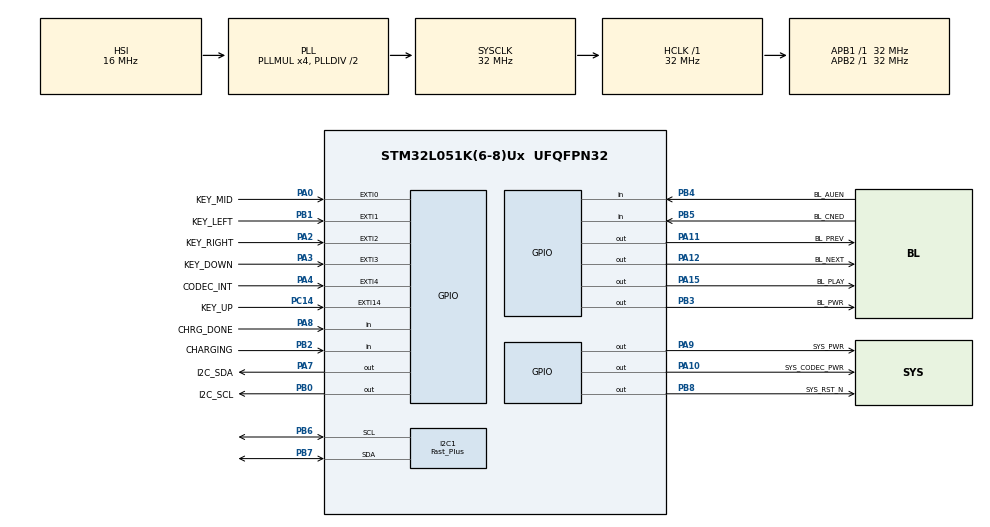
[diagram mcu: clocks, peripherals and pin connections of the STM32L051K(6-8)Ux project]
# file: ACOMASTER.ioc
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Dma.I2C1_TX.0.Direction=DMA_MEMORY_TO_PERIPH
Dma.I2C1_TX.0.Instance=DMA1_Channel2
Dma.I2C1_TX.0.MemDataAlignment=DMA_MDATAALIGN_BYTE
Dma.I2C1_TX.0.MemInc=DMA_MINC_ENABLE
Dma.I2C1_TX.0.Mode=DMA_NORMAL
Dma.I2C1_TX.0.PeriphDataAlignment=DMA_PDATAALIGN_BYTE
Dma.I2C1_TX.0.PeriphInc=DMA_PINC_DISABLE
Dma.I2C1_TX.0.Priority=DMA_PRIORITY_LOW
Dma.Request0=I2C1_TX
I2C1.I2C_Speed_Mode=I2C_Fast_Plus
I2C1.Timing=0x0040040C
Mcu.Family=STM32L0
Mcu.Name=STM32L051K(6-8)Ux
Mcu.Package=UFQFPN32
NVIC.DMA1_Channel2_3_IRQn=true\:1\:0\:true\:false\:true\:false\:true\:true
NVIC.EXTI0_1_IRQn=true\:1\:0\:true\:false\:true\:true\:true\:true
NVIC.EXTI2_3_IRQn=true\:1\:0\:true\:false\:true\:true\:true\:true
NVIC.EXTI4_15_IRQn=true\:1\:0\:true\:false\:true\:true\:true\:true
NVIC.FLASH_IRQn=true\:2\:0\:true\:false\:true\:true\:true\:true
NVIC.I2C1_IRQn=true\:1\:0\:true\:false\:true\:true\:true\:true
NVIC.RTC_IRQn=true\:1\:0\:true\:false\:true\:true\:true\:true
NVIC.TIM21_IRQn=true\:3\:0\:true\:false\:true\:true\:true\:true
NVIC.TIM6_DAC_IRQn=true\:2\:0\:true\:false\:true\:true\:true\:true
PA0.GPIO_Label=KEY_MID
PA0.GPIO_ModeDefaultEXTI=GPIO_MODE_IT_RISING
PA0.GPIO_PuPd=GPIO_PULLDOWN
PA0.Signal=GPXTI0
PA10.GPIO_Label=SYS_CODEC_PWR
PA10.Signal=GPIO_Output
PA11.GPIO_Label=BL_PREV
PA11.Signal=GPIO_Output
PA12.GPIO_Label=BL_NEXT
PA12.Signal=GPIO_Output
PA13.Mode=Serial_Wire
PA13.Signal=SYS_SWDIO
PA14.Mode=Serial_Wire
PA14.Signal=SYS_SWCLK
PA15.GPIO_Label=BL_PLAY
PA15.Signal=GPIO_Output
PA2.GPIO_Label=KEY_RIGHT
PA2.GPIO_ModeDefaultEXTI=GPIO_MODE_IT_FALLING
PA2.GPIO_PuPd=GPIO_PULLUP
PA2.Signal=GPXTI2
PA3.GPIO_Label=KEY_DOWN
PA3.GPIO_ModeDefaultEXTI=GPIO_MODE_IT_FALLING
PA3.GPIO_PuPd=GPIO_PULLUP
PA3.Signal=GPXTI3
PA4.GPIO_Label=CODEC_INT
PA4.GPIO_ModeDefaultEXTI=GPIO_MODE_IT_FALLING
PA4.Signal=GPXTI4
PA7.GPIO_Label=I2C_SDA
PA7.GPIO_ModeDefaultOutputPP=GPIO_MODE_OUTPUT_OD
PA7.GPIO_PuPd=GPIO_NOPULL
PA7.GPIO_Speed=GPIO_SPEED_FREQ_VERY_HIGH
PA7.PinState=GPIO_PIN_SET
PA7.Signal=GPIO_Output
PA8.GPIO_Label=CHRG_DONE
PA8.GPIO_PuPd=GPIO_PULLUP
PA8.Signal=GPIO_Input
PA9.GPIO_Label=SYS_PWR
PA9.Signal=GPIO_Output
PB0.GPIO_Label=I2C_SCL
PB0.GPIO_ModeDefaultOutputPP=GPIO_MODE_OUTPUT_OD
PB0.GPIO_PuPd=GPIO_NOPULL
PB0.GPIO_Speed=GPIO_SPEED_FREQ_VERY_HIGH
PB0.PinState=GPIO_PIN_SET
PB0.Signal=GPIO_Output
PB1.GPIO_Label=KEY_LEFT
PB1.GPIO_ModeDefaultEXTI=GPIO_MODE_IT_FALLING
PB1.GPIO_PuPd=GPIO_PULLUP
PB1.Signal=GPXTI1
PB2.GPIO_Label=CHARGING
PB2.GPIO_PuPd=GPIO_PULLUP
PB2.Signal=GPIO_Input
PB3.GPIO_Label=BL_PWR
PB3.PinState=GPIO_PIN_RESET
PB3.Signal=GPIO_Output
PB4.GPIO_Label=BL_AUEN
PB4.Signal=GPIO_Input
PB5.GPIO_Label=BL_CNED
PB5.Signal=GPIO_Input
PB6.Mode=I2C
PB6.Signal=I2C1_SCL
PB7.Mode=I2C
PB7.Signal=I2C1_SDA
PB8.GPIO_Label=SYS_RST_N
PB8.PinState=GPIO_PIN_SET
PB8.Signal=GPIO_Output
PC14-OSC32_IN.GPIO_Label=KEY_UP
PC14-OSC32_IN.GPIO_ModeDefaultEXTI=GPIO_MODE_IT_FALLING
PC14-OSC32_IN.GPIO_PuPd=GPIO_PULLUP
PC14-OSC32_IN.Signal=GPXTI14
ProjectManager.HeapSize=0x200
ProjectManager.StackSize=0x400
ProjectManager.TargetToolchain=MDK-ARM V5.32
RCC.AHBFreq_Value=32000000
RCC.APB1Freq_Value=32000000
RCC.APB1TimFreq_Value=32000000
RCC.APB2Freq_Value=32000000
RCC.APB2TimFreq_Value=32000000
RCC.HCLKFreq_Value=32000000
RCC.HSI16_VALUE=16000000
RCC.HSI_VALUE=16000000
RCC.LSE_VALUE=32768
RCC.MSI_VALUE=2097000
RCC.PLLMUL=RCC_PLLMUL_4
RCC.SYSCLKFreq_VALUE=32000000
RCC.SYSCLKSource=RCC_SYSCLKSOURCE_PLLCLK
RCC.VCOOutputFreq_Value=64000000
RTC.WakeUpClock=RTC_WAKEUPCLOCK_CK_SPRE_16BITS
RTC.WakeUpCounter=10
TIM21.AutoReloadPreload=TIM_AUTORELOAD_PRELOAD_ENABLE
TIM21.Period=499
TIM21.Prescaler=319
TIM22.Prescaler=31
TIM6.AutoReloadPreload=TIM_AUTORELOAD_PRELOAD_ENABLE
TIM6.Period=9999
TIM6.Prescaler=319
VP_RTC_VS_RTC_Activate.Mode=RTC_Enabled
VP_RTC_VS_RTC_WakeUp_intern.Mode=WakeUp
VP_TIM21_VS_ClockSourceITR.Mode=TriggerSource_ITR0
VP_TIM22_VS_ClockSourceITR.Mode=TriggerSource_ITR0
VP_TIM6_VS_ClockSourceINT.Mode=Enable_Timer
board=custom

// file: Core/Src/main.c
/* USER CODE BEGIN Header */
/**
  ******************************************************************************
  * @file           : main.c
  * @brief          : Main program body
  ******************************************************************************
  * @attention
  *
  * Copyright (c) 2023 STMicroelectronics.
  * All rights reserved.
  *
  * This software is licensed under terms that can be found in the LICENSE file
  * in the root directory of this software component.
  * If no LICENSE file comes with this software, it is provided AS-IS.
  *
  ******************************************************************************
  */
/* USER CODE END Header */
#include "main.h"
#include "dma.h"
#include "i2c.h"
#include "rtc.h"
#include "tim.h"
#include "gpio.h"

/* USER CODE BEGIN Includes */
#include "tasks.h"

#include "eeprom.h"
/* USER CODE END Includes */

/* USER CODE BEGIN PV */
uint8_t wd[5] = {0x45, 0xa7, 0x78, 0xfc, 0x01};
uint8_t rd[5] = {0x00};

/* USER CODE END PV */

void SystemClock_Config(void);

int main(void)
{

  /* MCU Configuration--------------------------------------------------------*/

  /* Reset of all peripherals, Initializes the Flash interface and the Systick. */
  HAL_Init();

  /* Configure the system clock */
  SystemClock_Config();

  /* Initialize all configured peripherals */
  MX_GPIO_Init();
  MX_DMA_Init();
  MX_TIM22_Init();
  MX_TIM21_Init();
  MX_TIM6_Init();
  MX_I2C1_Init();
  MX_RTC_Init();
  /* USER CODE BEGIN 2 */

	//这里先不使能RTC中断，设备息屏前再使能，重新生成代码后要修改rtc.c

  /* USER CODE END 2 */

  /* Infinite loop */
  /* USER CODE BEGIN WHILE */
  while (1)
  {

		main_FSM(&device_current_state, &device_last_state, 1);

		HAL_Delay(1);

    /* USER CODE END WHILE */

  }
}

void SystemClock_Config(void)
{
  RCC_OscInitTypeDef RCC_OscInitStruct = {0};
  RCC_ClkInitTypeDef RCC_ClkInitStruct = {0};
  RCC_PeriphCLKInitTypeDef PeriphClkInit = {0};

  /** Configure the main internal regulator output voltage
  */
  __HAL_PWR_VOLTAGESCALING_CONFIG(PWR_REGULATOR_VOLTAGE_SCALE1);

  /** Initializes the RCC Oscillators according to the specified parameters
  * in the RCC_OscInitTypeDef structure.
  */
  RCC_OscInitStruct.OscillatorType = RCC_OSCILLATORTYPE_HSI|RCC_OSCILLATORTYPE_LSI;
  RCC_OscInitStruct.HSIState = RCC_HSI_ON;
  RCC_OscInitStruct.HSICalibrationValue = RCC_HSICALIBRATION_DEFAULT;
  RCC_OscInitStruct.LSIState = RCC_LSI_ON;
  RCC_OscInitStruct.PLL.PLLState = RCC_PLL_ON;
  RCC_OscInitStruct.PLL.PLLSource = RCC_PLLSOURCE_HSI;
  RCC_OscInitStruct.PLL.PLLMUL = RCC_PLLMUL_4;
  RCC_OscInitStruct.PLL.PLLDIV = RCC_PLLDIV_2;
  if (HAL_RCC_OscConfig(&RCC_OscInitStruct) != HAL_OK)
  {
    Error_Handler();
  }

  /** Initializes the CPU, AHB and APB buses clocks
  */
  RCC_ClkInitStruct.ClockType = RCC_CLOCKTYPE_HCLK|RCC_CLOCKTYPE_SYSCLK
                              |RCC_CLOCKTYPE_PCLK1|RCC_CLOCKTYPE_PCLK2;
  RCC_ClkInitStruct.SYSCLKSource = RCC_SYSCLKSOURCE_PLLCLK;
  RCC_ClkInitStruct.AHBCLKDivider = RCC_SYSCLK_DIV1;
  RCC_ClkInitStruct.APB1CLKDivider = RCC_HCLK_DIV1;
  RCC_ClkInitStruct.APB2CLKDivider = RCC_HCLK_DIV1;

  if (HAL_RCC_ClockConfig(&RCC_ClkInitStruct, FLASH_LATENCY_1) != HAL_OK)
  {
    Error_Handler();
  }
  PeriphClkInit.PeriphClockSelection = RCC_PERIPHCLK_I2C1|RCC_PERIPHCLK_RTC;
  PeriphClkInit.I2c1ClockSelection = RCC_I2C1CLKSOURCE_PCLK1;
  PeriphClkInit.RTCClockSelection = RCC_RTCCLKSOURCE_LSI;
  if (HAL_RCCEx_PeriphCLKConfig(&PeriphClkInit) != HAL_OK)
  {
    Error_Handler();
  }
}

void Error_Handler(void)
{
  __disable_irq();
  while (1)
  {
  }
}
